# AT32F423 register map
Vendor: Keil; Series: AT32F423; File version: 1.0
CPU: CM4 r0p1, little endian, no MPU, FPU, 4 interrupt priority bits
Registers are 32-bit, read-write, reset 0x0 unless marked. A register's access mark holds for its fields unless they carry their own. Offsets are from the block's base; [hi:lo] are bit positions; {n}, {i} and the like mark numbered series; 'fields as' and 'values as' point back to an identical list.

## CRM — Clock and reset management
Base 0x40023800
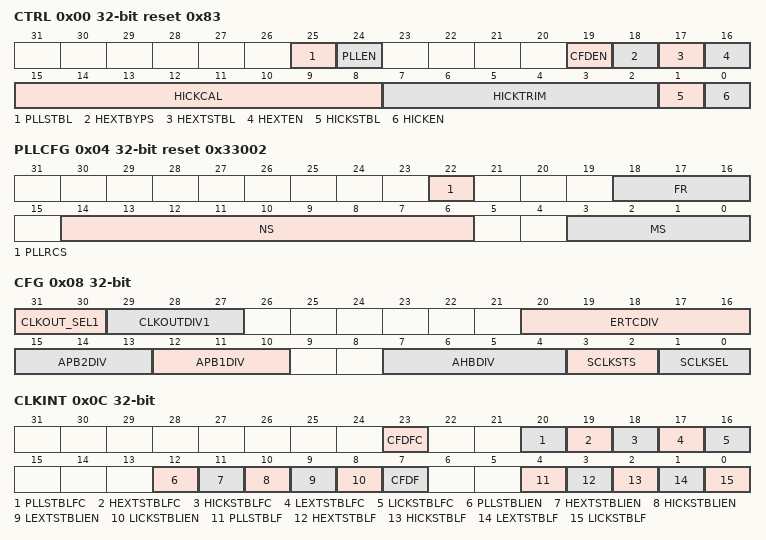
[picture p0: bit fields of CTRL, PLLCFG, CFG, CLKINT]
0x00 CTRL reset 0x83 — Clock control register
  [25] PLLSTBL ro — PLL clock ready flag
    0=NotReady; 1=Ready
  [24] PLLEN — PLL enable
    on read: 0=Disabled (PLL is disabled); 1=Enabled (PLL is enabled) | on write: 0=Disable (PLL disable); 1=Enable (PLL enable)
  [19] CFDEN — Clock failure detection enable
    on read: 0=Disabled (Clock failure detector is disabled); 1=Enabled (Clock failure detector is enabled) | on write: 0=Disable (Clock failure detector disable); 1=Enable (Clock failure detector enable)
  [18] HEXTBYPS — High speed exernal crystal bypass
    on read: 0=Disabled (High speed external crystal bypass is disabled); 1=Enabled (High speed external crystal bypass is enabled) | on write: 0=Disable (High speed external crystal bypass disable); 1=Enable (High speed external crystal bypass enable)
  [17] HEXTSTBL ro — High speed exernal crystal ready flag
    0=NotReady; 1=Ready
  [16] HEXTEN — High speed exernal crystal enable
    on read: 0=Disabled (High speed external crystal is disabled); 1=Enabled (High speed external crystal is enabled) | on write: 0=Disable (High speed external crystal disable); 1=Enable (High speed external crystal enable)
  [15:8] HICKCAL ro — High speed internal clock calibration
  [7:2] HICKTRIM — High speed internal clock trimming
  [1] HICKSTBL ro — High speed internal clock ready flag
    0=NotReady; 1=Ready
  [0] HICKEN — High speed internal clock enable
    on read: 0=Disabled (High speed internal clock is disabled); 1=Enabled (High speed internal clock is enabled) | on write: 0=Disable (High speed internal clock disable); 1=Enable (High speed internal clock enable)
0x04 PLLCFG reset 0x33002 — PLL configuration register (CRM_PLLCFG)
  [22] PLLRCS — PLL reference clock select
    0=HICK (HICK clock selected as PLL reference clock); 1=HEXT (HEXT clock selected as PLL reference clock)
  [18:16] FR — PLL post-division
    2=Div4 (Division by 4); 3=Div8 (Division by 8); 4=Div16 (Division by 16); 5=Div32 (Division by 32)
  [14:6] NS range 31..500 — PLL multiplication factor (31-500)
  [3:0] MS range 1..15 — PLL pre-division (1-15)
0x08 CFG — Clock configuration register(CRM_CFG)
  [31:30] CLKOUT_SEL1 — Clock output selection1
  [29:27] CLKOUTDIV1 — Clock output division1
  [20:16] ERTCDIV range 2..31 — HEXT division for ERTC clock (2-31)
  [15:13] APB2DIV — APB2 division
    4=Div2 (HCLK divided by 2); 5=Div4 (HCLK divided by 4); 6=Div8 (HCLK divided by 8); 7=Div16 (HCLK divided by 16); other=HCLK (The divided HCLK is used as APB clock)
  [12:10] APB1DIV — APB1 division
    values as APB2DIV
  [7:4] AHBDIV — AHB division
    8=Div2 (SCLK divided by 2); 9=Div4 (SCLK divided by 4); 10=Div8 (SCLK divided by 8); 11=Div16 (SCLK divided by 16); 12=Div64 (SCLK divided by 64); 13=Div128 (SCLK divided by 128); 14=Div256 (SCLK divided by 256); 15=Div512 (SCLK divided by 512); other=SCLK (The SCLK is used as AHB clock)
  [3:2] SCLKSTS ro — System Clock select Status
    0=HICK (System clock from HICK); 1=HEXT (System clock from HEXT); 2=PLL (System clock from PLL)
  [1:0] SCLKSEL — System clock select
    values as SCLKSTS
0x0C CLKINT — Clock interrupt register (CRM_CLKINT)
  [23] CFDFC wo write-1-clears — Clock failure detection interrupt clear
    0=Clear flag
  [20] PLLSTBLFC wo write-1-clears — PLL ready interrupt clear
    0=Clear flag
  [19] HEXTSTBLFC wo write-1-clears — HEXT ready interrupt clear
    0=Clear flag
  [18] HICKSTBLFC wo write-1-clears — HICK ready interrupt clear
    0=Clear flag
  [17] LEXTSTBLFC wo write-1-clears — LEXT ready interrupt clear
    0=Clear flag
  [16] LICKSTBLFC wo write-1-clears — LICK ready interrupt clear
    0=Clear flag
  [12] PLLSTBLIEN — PLL ready interrupt enable
    0=Disabled (Interrupt disabled); 1=Enabled (Interrupt enabled)
  [11] HEXTSTBLIEN — HEXT ready interrupt enable
    values as PLLSTBLIEN
  [10] HICKSTBLIEN — HICK ready interrupt enable
    values as PLLSTBLIEN
  [9] LEXTSTBLIEN — LEXT ready interrupt enable
    values as PLLSTBLIEN
  [8] LICKSTBLIEN — LICK ready interrupt enable
    values as PLLSTBLIEN
  [7] CFDF ro — Clock failure detection interrupt flag
    0=NoFailure (No clock failure); 1=Failure (Clock failure detected)
  [4] PLLSTBLF ro — PLL ready interrupt flag
    0=NotReady (PLL is not ready); 1=Ready (PLL is ready)
  [3] HEXTSTBLF ro — HEXT ready interrupt flag
    0=NotReady (HEXT is not ready); 1=Ready (HEXT is ready)
  [2] HICKSTBLF ro — HICK ready interrupt flag
    0=NotReady (HICK is not ready); 1=Ready (HICK is ready)
  [1] LEXTSTBLF ro — LEXT ready interrupt flag
    0=NotReady (LEXT is not ready); 1=Ready (LEXT is ready)
  [0] LICKSTBLF ro — LICK ready interrupt flag
    0=NotReady (LICK is not ready); 1=Ready (LICK is ready)
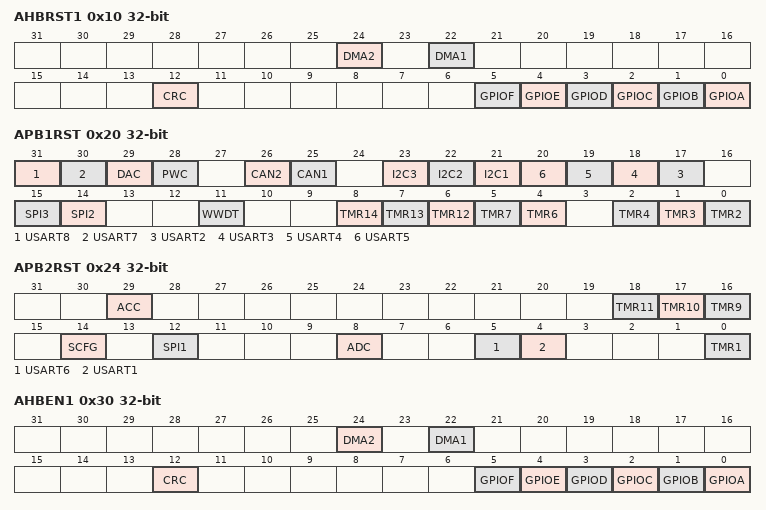
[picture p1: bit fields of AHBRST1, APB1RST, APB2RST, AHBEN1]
0x10 AHBRST1 — AHB peripheral reset register1 (CRM_AHBRST1)
  [all] fields
    on write: 1=Reset peripheral
  [24] DMA2 write-1-sets — DMA2 reset
  [22] DMA1 write-1-sets — DMA1 reset
  [12] CRC write-1-sets — CRC reset
  [5] GPIOF write-1-sets — IO port F reset
  [4] GPIOE write-1-sets — IO port E reset
  [3] GPIOD write-1-sets — IO port D reset
  [2] GPIOC write-1-sets — IO port C reset
  [1] GPIOB write-1-sets — IO port B reset
  [0] GPIOA write-1-sets — IO port A reset
0x14 AHBRST2 — AHB peripheral reset register 2 (CRM_AHBRST2)
  [7] OTGFS1 write-1-sets — OTGFS1 reset
    on write: 1=Reset peripheral
0x18 AHBRST3 — AHB peripheral reset register 3 (CRM_AHBRST3)
  [0] XMC write-1-sets — XMC reset
    on write: 1=Reset peripheral
0x20 APB1RST — APB1 peripheral reset register (CRM_APB1RST)
  [all] fields
    on write: 1=Reset peripheral
  [31] USART8 write-1-sets — USART8 reset
  [30] USART7 write-1-sets — USART7 reset
  [29] DAC write-1-sets — DAC reset
  [28] PWC write-1-sets — PWC reset
  [26] CAN2 write-1-sets — CAN2 reset
  [25] CAN1 write-1-sets — CAN1 reset
  [23] I2C3 write-1-sets — I2C3 reset
  [22] I2C2 write-1-sets — I2C2 reset
  [21] I2C1 write-1-sets — I2C1 reset
  [n+15] USART{n} write-1-sets (n=2..5) — USART{n} reset
  [15] SPI3 write-1-sets — SPI3 reset
  [14] SPI2 write-1-sets — SPI2 reset
  [11] WWDT write-1-sets — Window watchdog reset
  [8] TMR14 write-1-sets — Timer14 reset
  [7] TMR13 write-1-sets — Timer13 reset
  [6] TMR12 write-1-sets — Timer12 reset
  [5] TMR7 write-1-sets — Timer7 reset
  [4] TMR6 write-1-sets — Timer6 reset
  [2] TMR4 write-1-sets — Timer4 reset
  [1] TMR3 write-1-sets — Timer3 reset
  [0] TMR2 write-1-sets — Timer2 reset
0x24 APB2RST — APB2 peripheral reset register (CRM_APB2RST)
  [all] fields
    on write: 1=Reset peripheral
  [29] ACC write-1-sets — ACC reset
  [18] TMR11 write-1-sets — Timer 11 reset
  [17] TMR10 write-1-sets — Timer10 reset
  [16] TMR9 write-1-sets — Timer9 reset
  [14] SCFG write-1-sets — SCFG reset
  [12] SPI1 write-1-sets — SPI1 reset
  [8] ADC write-1-sets — ADC reset
  [5] USART6 write-1-sets — USART6 reset
  [4] USART1 write-1-sets — USART1 reset
  [0] TMR1 write-1-sets — Timer1 reset
0x30 AHBEN1 — AHB Peripheral Clock enable register 1 (CRM_AHBEN1)
  [all] fields
    0=Disable peripheral clock; 1=Enable peripheral clock
  [24] DMA2 — DMA2 clock enable
  [22] DMA1 — DMA1 clock enable
  [12] CRC — CRC clock enable
  [5] GPIOF — IO F clock enable
  [4] GPIOE — IO E clock enable
  [3] GPIOD — IO D clock enable
  [2] GPIOC — IO C clock enable
  [1] GPIOB — IO B clock enable
  [0] GPIOA — IO A clock enable
0x34 AHBEN2 — AHB peripheral clock enable register 2 (CRM_AHBEN2)
  [7] OTGFS1 — OTGFS1 clock enable
    0=Disable peripheral clock; 1=Enable peripheral clock
0x38 AHBEN3 — AHB peripheral clock enable register 3 (CRM_AHBEN3)
  [0] XMC — XMC clock enable
    0=Disable peripheral clock; 1=Enable peripheral clock
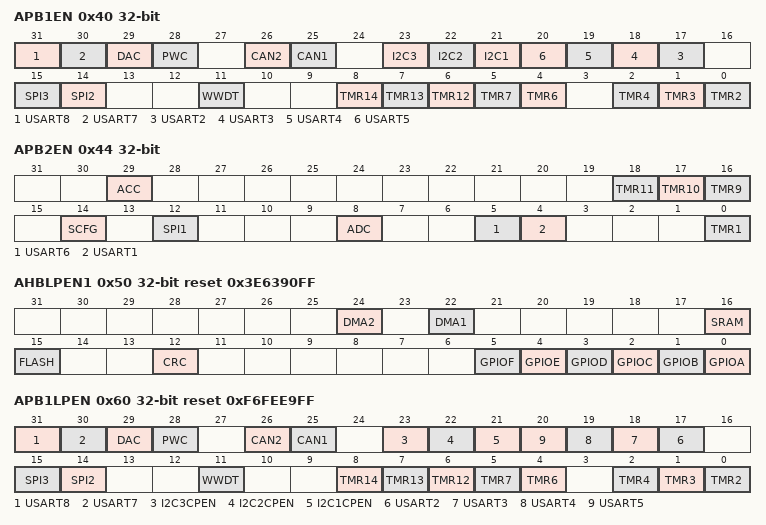
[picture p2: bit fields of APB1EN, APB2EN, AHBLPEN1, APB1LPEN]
0x40 APB1EN — APB1 peripheral clock enable register (CRM_APB1EN)
  [all] fields
    0=Disable peripheral clock; 1=Enable peripheral clock
  [31] USART8 — USART8 clock enable
  [30] USART7 — USART7 clock enable
  [29] DAC — DAC clock enable
  [28] PWC — PWC clock enable
  [26] CAN2 — CAN2 clock enable
  [25] CAN1 — CAN1 clock enable
  [23] I2C3 — I2C3 clock enable
  [22] I2C2 — I2C2 clock enable
  [21] I2C1 — I2C1 clock enable
  [n+15] USART{n} (n=2..5) — USART{n} clock enable
  [15] SPI3 — SPI3 clock enable
  [14] SPI2 — SPI2 clock enable
  [11] WWDT — WWDT clock enable
  [8] TMR14 — Timer14 clock enable
  [7] TMR13 — Timer13 clock enable
  [6] TMR12 — Timer12 clock enable
  [5] TMR7 — Timer7 clock enable
  [4] TMR6 — Timer6 clock enable
  [2] TMR4 — Timer4 clock enable
  [1] TMR3 — Timer3 clock enable
  [0] TMR2 — Timer2 clock enable
0x44 APB2EN — APB2 peripheral clock enable register (CRM_APB2EN)
  [all] fields
    0=Disable peripheral clock; 1=Enable peripheral clock
  [29] ACC — ACC clock enable
  [18] TMR11 — Timer11 clock enable
  [17] TMR10 — Timer10 clock enable
  [16] TMR9 — Timer9 clock enable
  [14] SCFG — SCFG clock enable
  [12] SPI1 — SPI1 clock enable
  [8] ADC — ADC clock enable
  [5] USART6 — USART6 clock enable
  [4] USART1 — USART1 clock enable
  [0] TMR1 — Timer1 clock enable
0x50 AHBLPEN1 reset 0x3E6390FF — AHB Low-power Peripheral Clock enable register 1 (CRM_AHBLPEN1)
  [all] fields
    0=Disable peripheral clock; 1=Enable peripheral clock
  [24] DMA2 — DMA2 clock enable during sleep mode
  [22] DMA1 — DMA1 clock enable during sleep mode
  [16] SRAM — SRAM clock enable during sleep mode
  [15] FLASH — Flash clock enable during sleep mode
  [12] CRC — CRC clock enable during sleep mode
  [5] GPIOF — IO F clock enable during sleep mode
  [4] GPIOE — IO E clock enable during sleep mode
  [3] GPIOD — IO D clock enable during sleep mode
  [2] GPIOC — IO C clock enable during sleep mode
  [1] GPIOB — IO B clock enable during sleep mode
  [0] GPIOA — IO A clock enable during sleep mode
0x54 AHBLPEN2 reset 0x8081 — AHB peripheral Low-power clock enable register 2 (CRM_AHBLPEN2)
  [7] OTGFS1 — OTGFS1 clock enable during sleep mode
    0=Disable peripheral clock; 1=Enable peripheral clock
0x58 AHBLPEN3 reset 0xC003 — AHB peripheral Low-power clock enable register 3 (CRM_AHBLPEN3)
  [0] XMC — XMC clock enable during sleep mode
    0=Disable peripheral clock; 1=Enable peripheral clock
0x60 APB1LPEN reset 0xF6FEE9FF — APB1 peripheral Low-power clock enable register (CRM_APB1LPEN)
  [all] fields
    0=Disable peripheral clock; 1=Enable peripheral clock
  [31] USART8 — USART8 clock enable during sleep mode
  [30] USART7 — USART7 clock enable during sleep mode
  [29] DAC — DAC clock enable during sleep mode
  [28] PWC — PWC clock enable during sleep mode
  [26] CAN2 — CAN2 clock enable during sleep mode
  [25] CAN1 — CAN1 clock enable during sleep mode
  [23] I2C3CPEN — I2C3 clock enable during sleep mode
  [22] I2C2CPEN — I2C2 clock enable during sleep mode
  [21] I2C1CPEN — I2C1 clock enable during sleep mode
  [n+15] USART{n} (n=2..5) — USART{n} clock enable during sleep mode
  [15] SPI3 — SPI3 clock enable during sleep mode
  [14] SPI2 — SPI2 clock enable during sleep mode
  [11] WWDT — WWDT clock enable during sleep mode
  [8] TMR14 — Timer14 clock enable during sleep mode
  [7] TMR13 — Timer13 clock enable during sleep mode
  [6] TMR12 — Timer12 clock enable during sleep mode
  [5] TMR7 — Timer7 clock enable during sleep mode
  [4] TMR6 — Timer6 clock enable during sleep mode
  [2] TMR4 — Timer4 clock enable during sleep mode
  [1] TMR3 — Timer3 clock enable during sleep mode
  [0] TMR2 — Timer2 clock enable during sleep mode
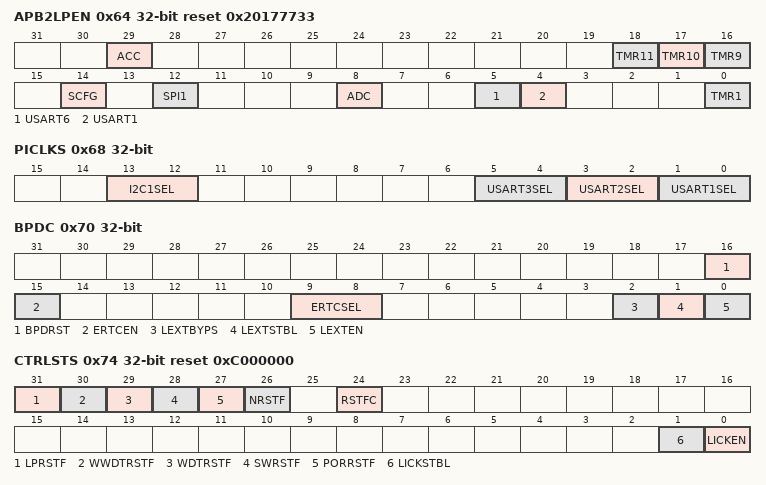
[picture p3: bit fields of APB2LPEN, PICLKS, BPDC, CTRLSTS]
0x64 APB2LPEN reset 0x20177733 — APB2 peripheral Low-power clock enable register (CRM_APB2LPEN)
  [all] fields
    0=Disable peripheral clock; 1=Enable peripheral clock
  [29] ACC — ACC clock enable during sleep mode
  [18] TMR11 — Timer11 clock enable during sleep mode
  [17] TMR10 — Timer10 clock enable during sleep mode
  [16] TMR9 — Timer9 clock enable during sleep mode
  [14] SCFG — SCFG clock enable during sleep mode
  [12] SPI1 — SPI1 clock enable during sleep mode
  [8] ADC — ADC clock enable during sleep mode
  [5] USART6 — USART6 clock enable during sleep mode
  [4] USART1 — USART1 clock enable during sleep mode
  [0] TMR1 — Timer1 clock enable during sleep mode
0x68 PICLKS — Peripheral independent clock register (CRM_PICLKS)
  [13:12] I2C1SEL — I2C1 clock select
  [5:4] USART3SEL — USART3 clock select
  [3:2] USART2SEL — USART2 clock select
  [1:0] USART1SEL — USART1 clock select
0x70 BPDC — Battery powered domain control register (CRM_BPDC)
  [16] BPDRST write-1-sets — Battery powered domain software reset
    on write: 1=Reset (Backup domain software reset)
  [15] ERTCEN — ERTC clock enable
    0=Disabled (ERTC clock is disabled); 1=Enabled (ERTC clock is enabled)
  [9:8] ERTCSEL — ERTC clock source selection
    0=NoClock; 1=LEXT; 2=LICK; 3=HEXT (Divided HEXT (with the ERTC_DIV bit in the CRM_CFG))
  [2] LEXTBYPS — Low speed external crystal bypass
    on read: 0=Disabled (LEXT bypass is disabled); 1=Enabled (LEXT bypass is enabled) | on write: 0=Disable (LEXT bypass disable); 1=Enable (LEXT bypass enable)
  [1] LEXTSTBL ro — Low speed external crystal ready
    0=NotReady (LEXT is not ready); 1=Ready (LEXT is ready)
  [0] LEXTEN — Low speed external crystal enable
    on read: 0=Disabled (Low speed external crystal is disabled); 1=Enabled (Low speed external crystal is enabled) | on write: 0=Disable (Low speed external crystal disable); 1=Enable (Low speed external crystal enable)
0x74 CTRLSTS reset 0xC000000 — Control/status register (CRM_CTRLSTS)
  [31] LPRSTF ro — Low-power reset flag
    0=NoReset (No low power reset occurred); 1=Reset (Low power reset occurred)
  [30] WWDTRSTF ro — Window watchdog timer reset flag
    0=NoReset (No window watchdog reset occurred); 1=Reset (Window watchdog reset occurred)
  [29] WDTRSTF ro — Watchdog timer reset flag
    0=NoReset (No watchdog reset occurred); 1=Reset (Watchdog reset occurred)
  [28] SWRSTF ro — Software reset flag
    0=NoReset (No software reset occurred); 1=Reset (Software reset occurred)
  [27] PORRSTF ro — POR/LVR reset flag
    0=NoReset (No POR/LVR reset occurred); 1=Reset (POR/LVR reset occurred)
  [26] NRSTF ro — PIN reset flag
    0=NoReset (No NRST pin reset occurred); 1=Reset (NRST pin reset occurred)
  [24] RSTFC write-1-clears — Reset reset flag
    on write: 0=Clear reset flags *RSTF
  [1] LICKSTBL ro — Low speed internal clock ready
    0=NotReady (LICK is not ready); 1=Ready (LICK is ready)
  [0] LICKEN — Low speed internal clock enable
    on read: 0=Disabled (LICK is disabled); 1=Enabled (LICK is enabled) | on write: 0=Disable (Low speed internal clock disable); 1=Enable (Low speed internal clock enable)
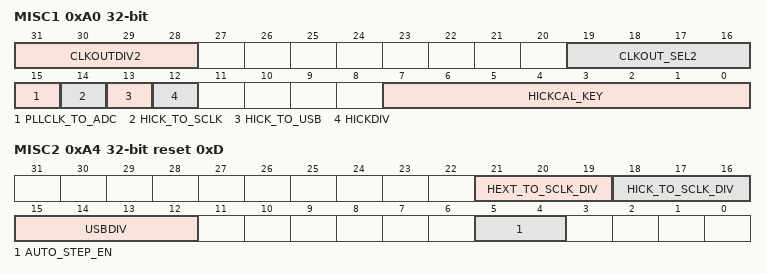
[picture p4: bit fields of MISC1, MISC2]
0xA0 MISC1 — Miscellaneous register1
  [31:28] CLKOUTDIV2 — Clock output division2
  [19:16] CLKOUT_SEL2 — Clock output select2
  [15] PLLCLK_TO_ADC — ADC clock source select
  [14] HICK_TO_SCLK — HICK to system clock
    0=HICKDiv6 (Fixed 8 MHz, that is, HICK/6); 1=HICKDiv (48 MHz or 8 MHz, depending on the HICKDIV)
  [13] HICK_TO_USB — HICK to usb clock
    0=PLLDiv (PLL or PLL division); 1=HICKDiv (48 MHz or 8 MHz, depending on the HICKDIV)
  [12] HICKDIV — HICK 6 divider selection
    0=Div6 (HICK is divided by 6 to generate the SCLK and USB clock when HICK_TO_SCLK or HICK_TO_USB is set to HICKDiv); 1=Div1 (HICK is not divided)
  [7:0] HICKCAL_KEY — HICKCAL write key value
    0=Invalid key (0). Write to HICKCAL is ignored; 90=Unlock key (0x5A). HICKCAL can be written
0xA4 MISC2 reset 0xD — Miscellaneous register2
  [21:19] HEXT_TO_SCLK_DIV — HEXT as system clock frequency division
  [18:16] HICK_TO_SCLK_DIV — HICK as system clock frequency division
  [15:12] USBDIV — USB division
    0=Div1_5 (USB clock is divided by 1.5); 1=Div1 (USB clock is not divided); 2=Div2_5 (USB clock is divided by 2.5); 3=Div2 (USB clock is divided by 2); 4=Div3_5 (USB clock is divided by 3.5); 5=Div3 (USB clock is divided by 3); 6=Div4_5 (USB clock is divided by 4.5); 7=Div4 (USB clock is divided by 4); 8=Div5_5 (USB clock is divided by 5.5); 9=Div5 (USB clock is divided by 5); 10=Div6_5 (USB clock is divided by 6.5); 11=Div6 (USB clock is divided by 6); 12=Div7 (USB clock is divided by 7)
  [5:4] AUTO_STEP_EN
    0=Disabled (Auto step mode disabled); 3=Enabled (Auto step mode enabled. When AHBDIV or SCLKSEL is modified, the auto step-by-step system clock switch is activated automatically.)
